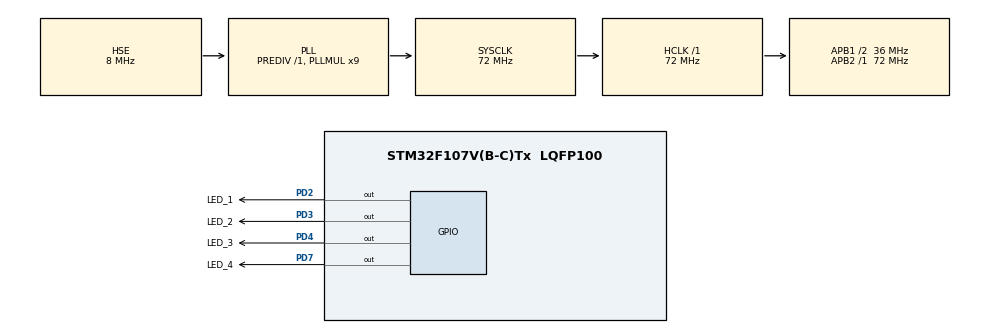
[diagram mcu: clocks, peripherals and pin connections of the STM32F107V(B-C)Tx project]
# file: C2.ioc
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Mcu.Family=STM32F1
Mcu.Name=STM32F107V(B-C)Tx
Mcu.Package=LQFP100
NVIC.PriorityGroup=NVIC_PRIORITYGROUP_4
OSC_IN.Mode=HSE-External-Oscillator
OSC_IN.Signal=RCC_OSC_IN
OSC_OUT.Mode=HSE-External-Oscillator
OSC_OUT.Signal=RCC_OSC_OUT
PA13.Mode=Serial_Wire
PA13.Signal=SYS_JTMS-SWDIO
PA14.Mode=Serial_Wire
PA14.Signal=SYS_JTCK-SWCLK
PD2.GPIO_Label=LED_1
PD2.PinState=GPIO_PIN_SET
PD2.Signal=GPIO_Output
PD3.GPIO_Label=LED_2
PD3.PinState=GPIO_PIN_SET
PD3.Signal=GPIO_Output
PD4.GPIO_Label=LED_3
PD4.PinState=GPIO_PIN_SET
PD4.Signal=GPIO_Output
PD7.GPIO_Label=LED_4
PD7.PinState=GPIO_PIN_SET
PD7.Signal=GPIO_Output
ProjectManager.HeapSize=0x200
ProjectManager.StackSize=0x400
ProjectManager.TargetToolchain=MDK-ARM V5
RCC.AHBFreq_Value=72000000
RCC.APB1CLKDivider=RCC_HCLK_DIV2
RCC.APB1Freq_Value=36000000
RCC.APB1TimFreq_Value=72000000
RCC.APB2Freq_Value=72000000
RCC.APB2TimFreq_Value=72000000
RCC.HCLKFreq_Value=72000000
RCC.PLLMUL=RCC_PLL_MUL9
RCC.PLLSourceVirtual=RCC_PLLSOURCE_HSE
RCC.SYSCLKFreq_VALUE=72000000
RCC.SYSCLKSource=RCC_SYSCLKSOURCE_PLLCLK
RCC.USBFreq_Value=48000000
board=custom

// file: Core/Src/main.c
/* USER CODE BEGIN Header */
/**
  ******************************************************************************
  * @file           : main.c
  * @brief          : Main program body
  ******************************************************************************
  * @attention
  *
  * <h2><center>&copy; Copyright (c) 2021 STMicroelectronics.
  * All rights reserved.</center></h2>
  *
  * This software component is licensed by ST under BSD 3-Clause license,
  * the "License"; You may not use this file except in compliance with the
  * License. You may obtain a copy of the License at:
  *                        opensource.org/licenses/BSD-3-Clause
  *
  ******************************************************************************
  */
/* USER CODE END Header */
#include "main.h"

/* USER CODE BEGIN Includes */
#include "Led.h"
/* USER CODE END Includes */

void SystemClock_Config(void);
static void MX_GPIO_Init(void);

int main(void)
{

  /* MCU Configuration--------------------------------------------------------*/

  /* Reset of all peripherals, Initializes the Flash interface and the Systick. */
  HAL_Init();

  /* Configure the system clock */
  SystemClock_Config();

  /* Initialize all configured peripherals */
  MX_GPIO_Init();

  /* Infinite loop */
  /* USER CODE BEGIN WHILE */
  while (1)
  {
      LED_Control(LED_ON);
	  HAL_Delay(500);
      LED_Control(LED_OFF);
      HAL_Delay(500);
    /* USER CODE END WHILE */

  }
}

void SystemClock_Config(void)
{
  RCC_OscInitTypeDef RCC_OscInitStruct = {0};
  RCC_ClkInitTypeDef RCC_ClkInitStruct = {0};

  /** Initializes the RCC Oscillators according to the specified parameters
  * in the RCC_OscInitTypeDef structure.
  */
  RCC_OscInitStruct.OscillatorType = RCC_OSCILLATORTYPE_HSE;
  RCC_OscInitStruct.HSEState = RCC_HSE_ON;
  RCC_OscInitStruct.HSEPredivValue = RCC_HSE_PREDIV_DIV1;
  RCC_OscInitStruct.HSIState = RCC_HSI_ON;
  RCC_OscInitStruct.Prediv1Source = RCC_PREDIV1_SOURCE_HSE;
  RCC_OscInitStruct.PLL.PLLState = RCC_PLL_ON;
  RCC_OscInitStruct.PLL.PLLSource = RCC_PLLSOURCE_HSE;
  RCC_OscInitStruct.PLL.PLLMUL = RCC_PLL_MUL9;
  RCC_OscInitStruct.PLL2.PLL2State = RCC_PLL_NONE;
  if (HAL_RCC_OscConfig(&RCC_OscInitStruct) != HAL_OK)
  {
    Error_Handler();
  }
  /** Initializes the CPU, AHB and APB buses clocks
  */
  RCC_ClkInitStruct.ClockType = RCC_CLOCKTYPE_HCLK|RCC_CLOCKTYPE_SYSCLK
                              |RCC_CLOCKTYPE_PCLK1|RCC_CLOCKTYPE_PCLK2;
  RCC_ClkInitStruct.SYSCLKSource = RCC_SYSCLKSOURCE_PLLCLK;
  RCC_ClkInitStruct.AHBCLKDivider = RCC_SYSCLK_DIV1;
  RCC_ClkInitStruct.APB1CLKDivider = RCC_HCLK_DIV2;
  RCC_ClkInitStruct.APB2CLKDivider = RCC_HCLK_DIV1;

  if (HAL_RCC_ClockConfig(&RCC_ClkInitStruct, FLASH_LATENCY_2) != HAL_OK)
  {
    Error_Handler();
  }
  /** Configure the Systick interrupt time
  */
  __HAL_RCC_PLLI2S_ENABLE();
}

static void MX_GPIO_Init(void)
{
  GPIO_InitTypeDef GPIO_InitStruct = {0};

  /* GPIO Ports Clock Enable */
  __HAL_RCC_GPIOA_CLK_ENABLE();
  __HAL_RCC_GPIOD_CLK_ENABLE();

  /*Configure GPIO pin Output Level */
  HAL_GPIO_WritePin(GPIOD, LED_1_Pin|LED_2_Pin|LED_3_Pin|LED_4_Pin, GPIO_PIN_SET);

  /*Configure GPIO pins : LED_1_Pin LED_2_Pin LED_3_Pin LED_4_Pin */
  GPIO_InitStruct.Pin = LED_1_Pin|LED_2_Pin|LED_3_Pin|LED_4_Pin;
  GPIO_InitStruct.Mode = GPIO_MODE_OUTPUT_PP;
  GPIO_InitStruct.Pull = GPIO_NOPULL;
  GPIO_InitStruct.Speed = GPIO_SPEED_FREQ_LOW;
  HAL_GPIO_Init(GPIOD, &GPIO_InitStruct);

}

void Error_Handler(void)
{
  __disable_irq();
  while (1)
  {
  }
}

/************************ (C) COPYRIGHT STMicroelectronics *****END OF FILE****/
